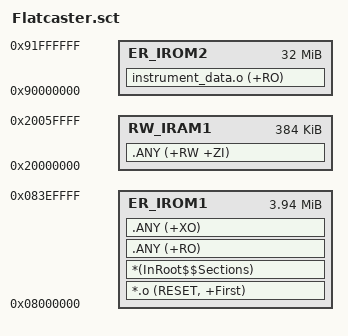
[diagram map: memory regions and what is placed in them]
; *************************************************************
; *** Scatter-Loading Description File generated by uVision ***
; *************************************************************

LR_IROM1 0x08000000 0x003F0000  {    ; load region size_region
  ER_IROM1 0x08000000 0x003F0000  {  ; load address = execution address
   *.o (RESET, +First)
   *(InRoot$$Sections)
   .ANY (+RO)
   .ANY (+XO)
  }
  RW_IRAM1 0x20000000 0x00060000  {  ; RW data
   .ANY (+RW +ZI)
  }
}

LR_IROM2 0x90000000 0x02000000  {
  ER_IROM2 0x90000000 0x02000000  {  ; load address = execution address
    instrument_data.o (+RO)
  }
}
